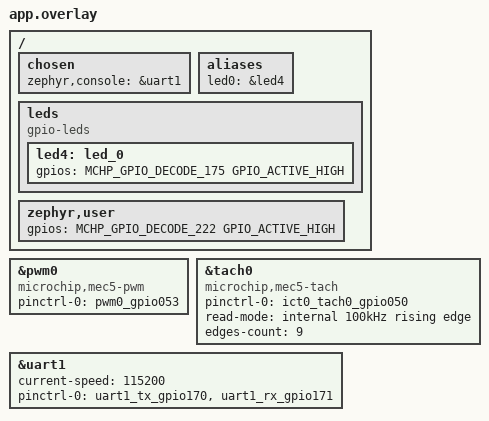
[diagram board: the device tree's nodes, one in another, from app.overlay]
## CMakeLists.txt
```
# SPDX-License-Identifier: Apache-2.0

cmake_minimum_required(VERSION 3.20.0)

find_package(Zephyr REQUIRED HINTS $ENV{ZEPHYR_BASE})
project(pwm)

target_sources(app PRIVATE src/main.c)
```

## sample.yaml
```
tests:
  boards.mec_assy6941.pwm:
    build_only: true
    platform_allow:
      - mec_assy6941_mec1743qlj
      - mec_assy6941_mec1743qsz
      - mec_assy6941_mec1753qlj
      - mec_assy6941_mec1753qsz
    tags: drivers pwm
```

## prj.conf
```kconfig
CONFIG_LOG=y
CONFIG_LOG_MODE_IMMEDIATE=y
#CONFIG_LOG_MODE_MINIMAL=y
#CONFIG_LOG_MODE_DEFERRED=y
#CONFIG_LOG_BUFFER_SIZE=2048
CONFIG_LOG_BACKEND_UART=n
CONFIG_LOG_BACKEND_SWO=y
CONFIG_LOG_BACKEND_SWO_REF_FREQ_HZ=96000000
CONFIG_LOG_BACKEND_SWO_FREQ_HZ=4000000

CONFIG_GPIO=y
CONFIG_PINCTRL=y
CONFIG_LED=y
CONFIG_SERIAL=y
CONFIG_CONSOLE=y
CONFIG_UART_CONSOLE=y
CONFIG_PWM=y

# CONFIG_PM=n

# Help debug new code
# CONFIG_DEBUG_COREDUMP=y
# CONFIG_TRAP_UNALIGNED_ACCESS=y
# CONFIG_SOC_MEC5_DEBUG_AND_TRACING=y
# CONFIG_SOC_MEC5_DEBUG_AND_SWV_TRACING=y
CONFIG_DEBUG=y

#CONFIG_COMPILER_TRACK_MACRO_EXPANSION=y
#CONFIG_COMPILER_SAVE_TEMPS=y
```

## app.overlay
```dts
/*
 * Copyright (c) 2024 Microchip Technology Inc.
 *
 * SPDX-License-Identifier: Apache-2.0
 */

#include <zephyr/dt-bindings/gpio/gpio.h>
#include <zephyr/dt-bindings/gpio/microchip-xec-gpio.h>

/*
 * MEC5_ASSY6941
 * JP7 2-3 GPIO055 pulled-down via 10K to ground.
 * JP23 14-15 selects GPIO055 as SHD_nCS0
 * JP42 1-2 connects 1.8V
 * JP60 2-3 VTR2 is powered by 1.8V
 * NOTE: VTR3 is always 1.8V
 *
 * Boot-ROM GPIO055 as RSMRST#
 * GPIO Control register value = 0x0200
 * Output, push-pull, driver low, no internal pulls,
 * interrupt detection = level low, alternate out enabled.
 * ROM drives pin high(inactive) using alternate out (bit[16] of control register)
 * Control register = 0x10200
 *
 * GPIO175/CMP_VOUT1/PWM8_ALT on schematic, LED4 on silkscreen.
 *
 * PWM0 pin jumpers:
 * JP76 1-2 OFF do not connect to 100K pull-up to VTR2
 * JP79 1-2 ON connect GPIO053 from SoC to FAN_PWM0 signal to P4 1x4 pin 4
 *   (pulled up with 10K to VTR2)

 * Headers:
 * P4 1x4
 *	Pin 1 = GND
 *	Pin 2 = JP78-2 selecting +12V or +5V
 *	Pin 3 = FAN_TACH0
 *	Pin 4 = FAN_PWM0
 *
 * J30 2x8
 *	Pins 2, 10 = FAN_PWM0
 *	Pin 1 = FAN_TACH0
 *	Pin 9 = FAN_TACH4
 *
 * Switch S4 through Schmidt trigger U19B to GPIO162/nVCI_IN1
 * Fly-wire GPIO162 to GPIO222
 * J57 3-4
 * JP146 2-3 selects JP147 pull-up voltage rail as VBAT_CHIP
 * JP24 3x16 34-35 to select GPIO222/PROCHOT_IN_ALT
 * JP147-27 to JP76-11 (GPIO222/PROCHOT_IN_ALT)
 *
 */

/ {
	chosen {
		zephyr,console = &uart1;
	};

	aliases {
		led0 = &led4;
	};

	leds {
		compatible = "gpio-leds";
		led4: led_0 {
			gpios = <MCHP_GPIO_DECODE_175 GPIO_ACTIVE_HIGH>;
		};
	};

	zephyr,user {
		gpios = <MCHP_GPIO_DECODE_222 GPIO_ACTIVE_HIGH>;
	};
};

&pwm0 {
	compatible = "microchip,mec5-pwm";
	pinctrl-0 = <&pwm0_gpio053>;
	pinctrl-names = "default";
	status = "okay";
};

&tach0 {
	compatible = "microchip,mec5-tach";
	pinctrl-0 = <&ict0_tach0_gpio050>;
	pinctrl-names = "default";
	read-mode = "internal 100kHz rising edge";
	edges-count = "9";
	status = "okay";
};

&uart1 {
	current-speed = <115200>;
	status = "okay";
	pinctrl-0 = <&uart1_tx_gpio170 &uart1_rx_gpio171>;
	pinctrl-names = "default";
};
```

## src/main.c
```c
/*
 * Copyright (c) 2012-2014 Wind River Systems, Inc.
 * Copyright (c) 2022 Microchip Technology, Inc.
 *
 * SPDX-License-Identifier: Apache-2.0
 */

#include <errno.h>
#include <stdint.h>
#include <string.h>

#include <zephyr/device.h>
#include <zephyr/devicetree.h>
#include <zephyr/kernel.h>
#include <zephyr/drivers/gpio.h>
#include <zephyr/drivers/led.h>
#include <zephyr/drivers/pinctrl.h>
#include <zephyr/drivers/pwm.h>
#include <zephyr/sys/sys_io.h>

#include <zephyr/logging/log_ctrl.h>
#include <zephyr/logging/log.h>
LOG_MODULE_REGISTER(app, CONFIG_LOG_DEFAULT_LEVEL);

#include <soc.h>

#define ZEPHYR_USER_NODE DT_PATH(zephyr_user)
const struct gpio_dt_spec button_s4_dt = GPIO_DT_SPEC_GET_BY_IDX(ZEPHYR_USER_NODE, gpios, 0);

static const struct device *pwm_dev = DEVICE_DT_GET(DT_NODELABEL(pwm0));

static volatile uint32_t spin_val;
static volatile int ret_val;
static volatile bool run;

static void spin_on(uint32_t id, int rval);

#define GPIO_0162_PIN_MASK BIT(18)
static void gpio_cb(const struct device *port,
		    struct gpio_callback *cb,
		    gpio_port_pins_t pins);

static struct gpio_callback gpio_cb_button_s4;
static struct k_sem button_s4_sync;

int main(void)
{
	int ret = 0;
	uint32_t channel = 0, flags = 0;
	uint32_t period_cycles = 0, pulse_cycles = 0;
	uint32_t period_cycles2 = 0, pulse_cycles2 = 0;
	uint64_t cycles = 0;

	LOG_INF("MEC5 PWMN sample: board: %s", DT_N_P_compatible_IDX_0);

	k_sem_init(&button_s4_sync, 0, 1);

	if (!device_is_ready(pwm_dev)) {
		LOG_ERR("PWM device is not ready! (%d)", -3);
		spin_on((uint32_t)__LINE__, -3);
	}

	ret = gpio_pin_configure_dt(&button_s4_dt, GPIO_INPUT);
	if (ret) {
		LOG_ERR("Configure Target_nReady GPIO as output hi (%d)", ret);
		spin_on((uint32_t)__LINE__, 2);
	}

	gpio_init_callback(&gpio_cb_button_s4, gpio_cb, GPIO_0162_PIN_MASK);
	ret = gpio_add_callback_dt(&button_s4_dt, &gpio_cb_button_s4);
	if (ret) {
		LOG_ERR("GPIO add callback for button S4 pin error (%d)", ret);
		spin_on((uint32_t)__LINE__, ret);
	}

	/* button OFF is low, depressed is high, trigger on rising edge */
	ret =  gpio_pin_interrupt_configure_dt(&button_s4_dt,
					       (GPIO_INPUT | GPIO_INT_EDGE_RISING));
	if (ret) {
		LOG_ERR("GPIO interrupt config for button S4 error (%d)", ret);
		spin_on((uint32_t)__LINE__, ret);
	}

	run = true;

	ret = pwm_get_cycles_per_sec(pwm_dev, channel, &cycles);
	if (ret) {
		LOG_ERR("PWM API get cycles error (%d)", ret);
		spin_on((uint32_t)__LINE__, ret);
	}

	LOG_INF("PWM get cycles returned %llu cycles per second", cycles);

	/* 1KHz 50% duty cycle */
	period_cycles = (uint32_t)(cycles / 1000u);
	pulse_cycles = period_cycles / 2u;

	/* 5KHz 33% duty cycles */
	period_cycles2 = (uint32_t)(cycles / 5000u);
	pulse_cycles2 = period_cycles2 / 3u;

	while (run) {
		LOG_INF("1KHz 50 percent duty: period cycles = %u  pulse cycles = %u",
			period_cycles, pulse_cycles);
		ret = pwm_set_cycles(pwm_dev, channel, period_cycles, pulse_cycles, flags);
		if (ret) {
			LOG_ERR("PWM API set cycles error (%d)", ret);
			spin_on((uint32_t)__LINE__, ret);
		}

		k_sem_take(&button_s4_sync, K_FOREVER); /* decrements count */
		/* k_sem_reset(&button_s4_sync); */

		LOG_INF("5KHz 33 percent duty: period cycles = %u  pulse cycles = %u",
			period_cycles2, pulse_cycles2);
		ret = pwm_set_cycles(pwm_dev, channel, period_cycles2, pulse_cycles2, flags);
		if (ret) {
			LOG_ERR("PWM API set cycles error (%d)", ret);
			spin_on((uint32_t)__LINE__, ret);
		}

		k_sem_take(&button_s4_sync, K_FOREVER);
		/* k_sem_reset(&button_s4_sync); */

		LOG_INF("PWM turn off");
		ret = pwm_set_cycles(pwm_dev, channel, period_cycles2, 0, flags);
		if (ret) {
			LOG_ERR("PWM API set OFF cycles error (%d)", ret);
			spin_on((uint32_t)__LINE__, ret);
		}

		k_sem_take(&button_s4_sync, K_FOREVER);
		/* k_sem_reset(&button_s4_sync); */

		LOG_INF("PWM turn ON");
		ret = pwm_set_cycles(pwm_dev, channel, period_cycles2, period_cycles2, flags);
		if (ret) {
			LOG_ERR("PWM API set ON cycles error (%d)", ret);
			spin_on((uint32_t)__LINE__, ret);
		}

		k_sem_take(&button_s4_sync, K_FOREVER);
		/* k_sem_reset(&button_s4_sync); */

	}

	LOG_INF("Application Done (%d)", ret);
	spin_on(256, 0);

	return 0;
}

/* GPIO callbacks */
static void gpio_cb(const struct device *port,
		    struct gpio_callback *cb,
		    gpio_port_pins_t pins)
{
	if (pins & GPIO_0162_PIN_MASK) {
		LOG_INF("GPIO CB: Button S4 falling edge");
		k_sem_give(&button_s4_sync);
	} else {
		LOG_ERR("GPIO CB: unknown pin 0x%08x", pins);
	}
}

static void spin_on(uint32_t id, int rval)
{
	spin_val = id;
	ret_val = rval;

	log_panic(); /* flush log buffers */

	while (spin_val) {
		;
	}
}
```
